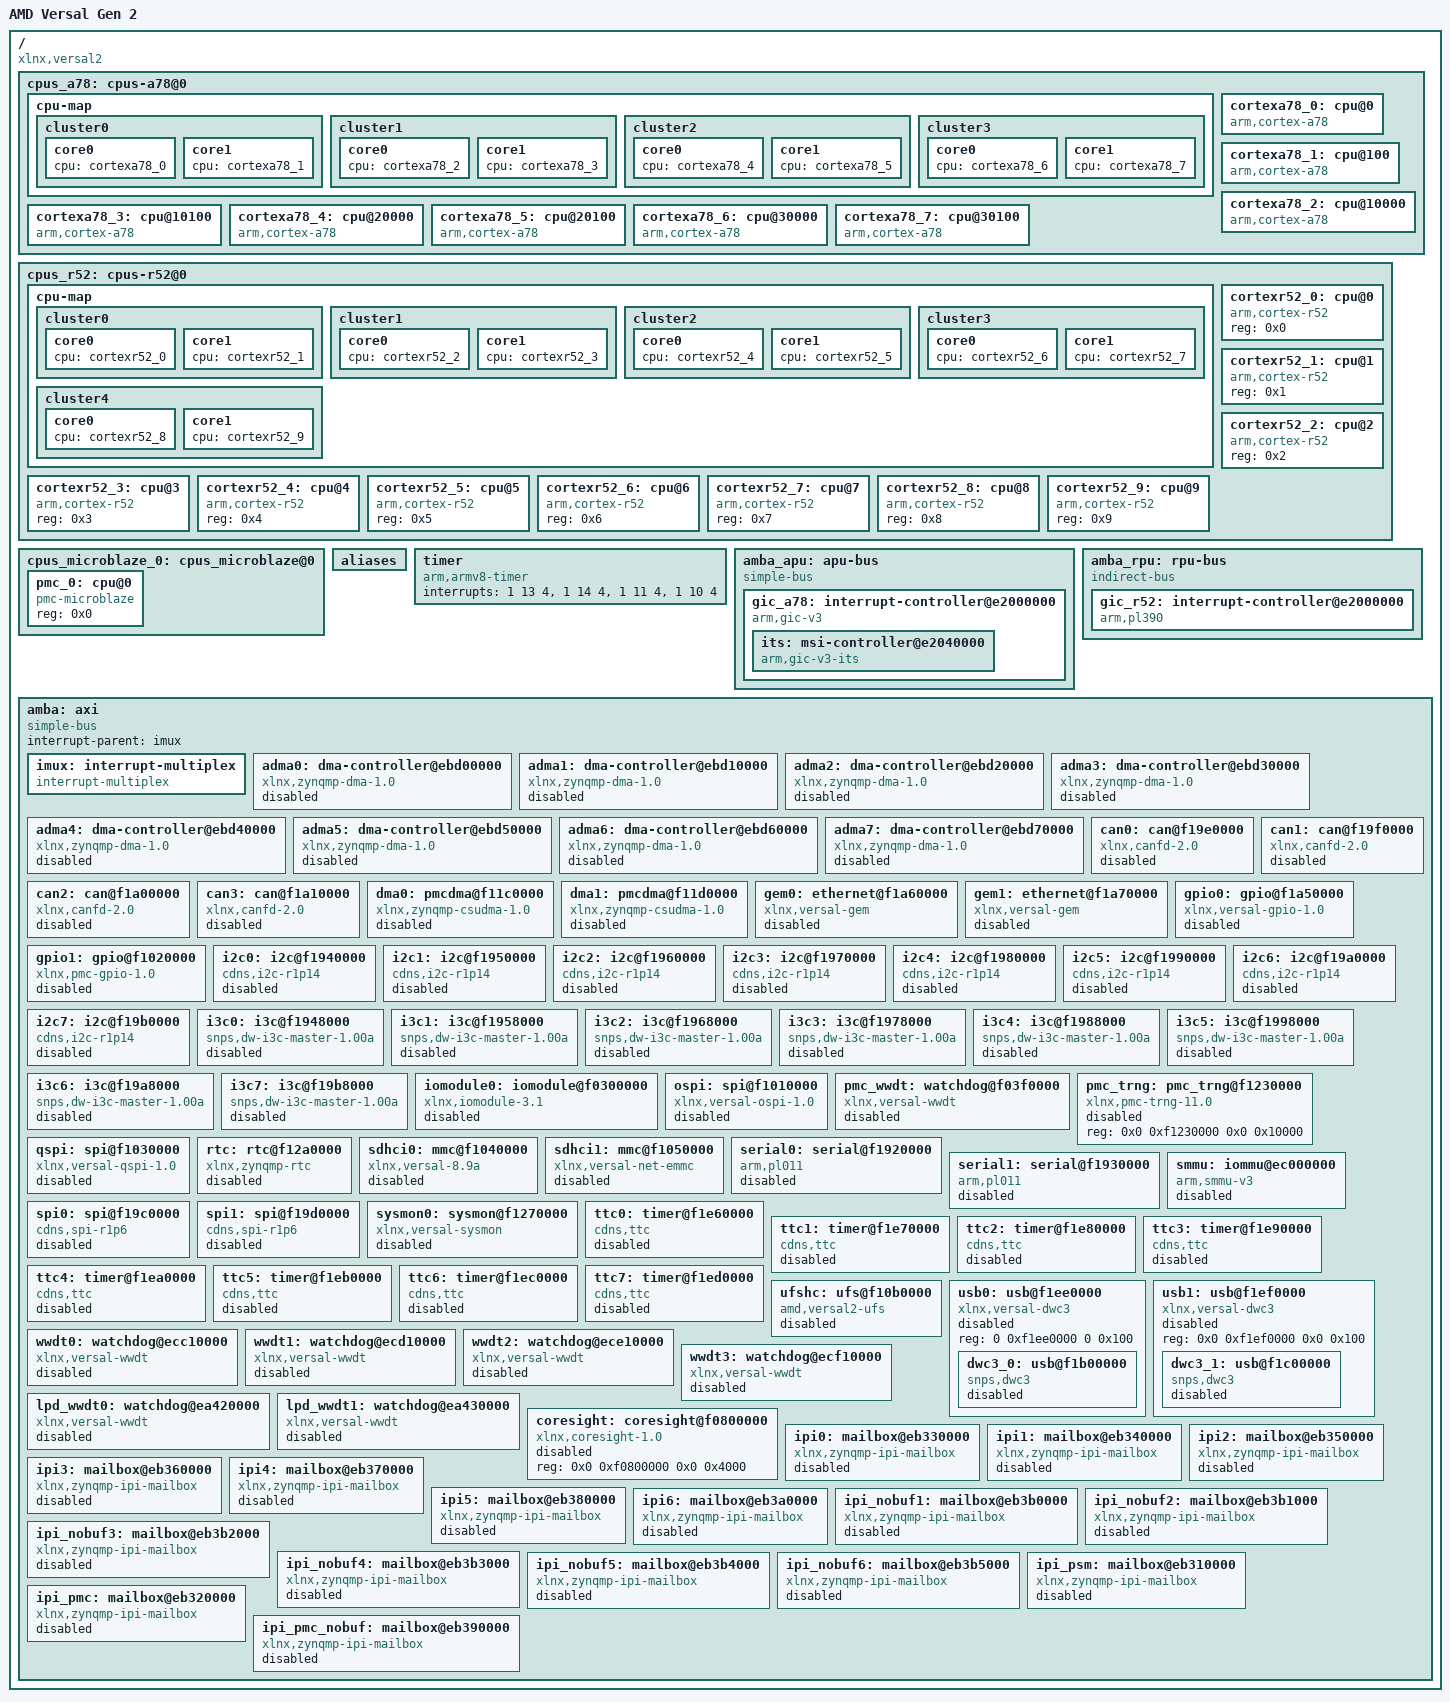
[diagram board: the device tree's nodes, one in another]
// SPDX-License-Identifier: GPL-2.0
/*
 * dts file for AMD Versal Gen 2
 *
 * Copyright (C) 2024, Advanced Micro Devices, Inc.
 *
 * Michal Simek <michal.simek@amd.com>
 */

/dts-v1/;

/ {
	compatible = "xlnx,versal2";
	model = "AMD Versal Gen 2";
	#address-cells = <2>;
	#size-cells = <2>;
	interrupt-parent = <&imux>;

	cpus_a78: cpus-a78@0 {
		#address-cells = <1>;
		#size-cells = <0>;
		cpu-map {
			cluster0 {
				core0 {
					cpu = <&cortexa78_0>;
				};
				core1 {
					cpu = <&cortexa78_1>;
				};
			};
			cluster1 {
				core0 {
					cpu = <&cortexa78_2>;
				};
				core1 {
					cpu = <&cortexa78_3>;
				};
			};
			cluster2 {
				core0 {
					cpu = <&cortexa78_4>;
				};
				core1 {
					cpu = <&cortexa78_5>;
				};
			};
			cluster3 {
				core0 {
					cpu = <&cortexa78_6>;
				};
				core1 {
					cpu = <&cortexa78_7>;
				};
			};
		};

		cortexa78_0: cpu@0 {
			compatible = "arm,cortex-a78";
			device_type = "cpu";
			enable-method = "psci";
			reg = <0>;
		};
		cortexa78_1: cpu@100 {
			compatible = "arm,cortex-a78";
			device_type = "cpu";
			enable-method = "psci";
			reg = <0x100>;
		};
		cortexa78_2: cpu@10000 {
			compatible = "arm,cortex-a78";
			device_type = "cpu";
			enable-method = "psci";
			reg = <0x10000>;
		};
		cortexa78_3: cpu@10100 {
			compatible = "arm,cortex-a78";
			device_type = "cpu";
			enable-method = "psci";
			reg = <0x10100>;
		};
		cortexa78_4: cpu@20000 {
			compatible = "arm,cortex-a78";
			device_type = "cpu";
			enable-method = "psci";
			reg = <0x20000>;
		};
		cortexa78_5: cpu@20100 {
			compatible = "arm,cortex-a78";
			device_type = "cpu";
			enable-method = "psci";
			reg = <0x20100>;
		};
		cortexa78_6: cpu@30000 {
			compatible = "arm,cortex-a78";
			device_type = "cpu";
			enable-method = "psci";
			reg = <0x30000>;
		};
		cortexa78_7: cpu@30100 {
			compatible = "arm,cortex-a78";
			device_type = "cpu";
			enable-method = "psci";
			reg = <0x30100>;
		};
	};

	cpus_r52: cpus-r52@0 {
		#address-cells = <1>;
		#size-cells = <0>;
		cpu-map {
			cluster0 {
				core0 {
					cpu = <&cortexr52_0>;
				};
				core1 {
					cpu = <&cortexr52_1>;
				};
			};

			cluster1 {
				core0 {
					cpu = <&cortexr52_2>;
				};

				core1 {
					cpu = <&cortexr52_3>;
				};
			};

			cluster2 {
				core0 {
					cpu = <&cortexr52_4>;
				};
				core1 {
					cpu = <&cortexr52_5>;
				};
			};

			cluster3 {
				core0 {
					cpu = <&cortexr52_6>;
				};
				core1 {
					cpu = <&cortexr52_7>;
				};
			};

			cluster4 {
				core0 {
					cpu = <&cortexr52_8>;
				};
				core1 {
					cpu = <&cortexr52_9>;
				};
			};
		};

		cortexr52_0: cpu@0 {
			compatible = "arm,cortex-r52";
			device_type = "cpu";
			reg = <0x0>;
		};

		cortexr52_1: cpu@1 {
			compatible = "arm,cortex-r52";
			device_type = "cpu";
			reg = <0x1>;
		};

		cortexr52_2: cpu@2 {
			compatible = "arm,cortex-r52";
			device_type = "cpu";
			reg = <0x2>;
		};

		cortexr52_3: cpu@3 {
			compatible = "arm,cortex-r52";
			device_type = "cpu";
			reg = <0x3>;
		};

		cortexr52_4: cpu@4 {
			compatible = "arm,cortex-r52";
			device_type = "cpu";
			reg = <0x4>;
		};

		cortexr52_5: cpu@5 {
			compatible = "arm,cortex-r52";
			device_type = "cpu";
			reg = <0x5>;
		};

		cortexr52_6: cpu@6 {
			compatible = "arm,cortex-r52";
			device_type = "cpu";
			reg = <0x6>;
		};

		cortexr52_7: cpu@7 {
			compatible = "arm,cortex-r52";
			device_type = "cpu";
			reg = <0x7>;
		};

		cortexr52_8: cpu@8 {
			compatible = "arm,cortex-r52";
			device_type = "cpu";
			reg = <0x8>;
		};

		cortexr52_9: cpu@9 {
			compatible = "arm,cortex-r52";
			device_type = "cpu";
			reg = <0x9>;
		};
	};

	cpus_microblaze_0: cpus_microblaze@0 {
		#address-cells = <1>;
		#size-cells = <0>;
		pmc_0: cpu@0 {
			compatible = "pmc-microblaze";
			device_type = "cpu";
			reg = <0x0>;
		};
	};

	aliases {
		serial0 = &serial0;
		serial1 = &serial1;
		mmc0 = &sdhci0;
		mmc1 = &sdhci1;
		i2c0 = &i2c0;
		i2c1 = &i2c1;
		i2c2 = &i2c2;
		i2c3 = &i2c3;
		i2c4 = &i2c4;
		i2c5 = &i2c5;
		i2c6 = &i2c6;
		i2c7 = &i2c7;
		spi0 = &ospi;
		spi1 = &qspi;
		spi2 = &spi0;
		spi3 = &spi1;
	};

	timer: timer {
		compatible = "arm,armv8-timer";
		interrupts = <1 13 4>, <1 14 4>, <1 11 4>, <1 10 4>;
	};

	amba_apu: apu-bus {
		compatible = "simple-bus";
		#address-cells = <2>;
		#size-cells = <2>;
		ranges;
		interrupt-parent = <&gic_a78>;
		u-boot,dm-pre-reloc;

		gic_a78: interrupt-controller@e2000000 {
			compatible = "arm,gic-v3";
			#interrupt-cells = <3>;
			reg = <0 0xe2000000 0 0x10000>,
			      <0 0xe2060000 0 0x200000>;
			interrupt-controller;
			interrupt-parent = <&gic_a78>;
			interrupts = <1 9 4>;
			#address-cells = <2>;
			#size-cells = <2>;
			ranges;
			its: msi-controller@e2040000 {
				compatible = "arm,gic-v3-its";
				msi-controller;
				#msi-cells = <1>;
				reg = <0 0xe2040000 0 0x20000>;
			};
		};
	};

	// Check the RPU GIC address
	amba_rpu: rpu-bus {
		compatible = "indirect-bus";
		#address-cells = <0x2>;
		#size-cells = <0x2>;
		ranges;
		interrupt-parent = <&gic_r52>;
		u-boot,dm-pre-reloc;

		gic_r52: interrupt-controller@e2000000 {
			compatible = "arm,pl390";
			#interrupt-cells = <3>;
			interrupt-controller;
			interrupt-parent = <&gic_r52>;
			interrupts = <1 9 4>;
			#address-cells = <2>;
			#size-cells = <2>;
			reg = <0x0 0xe2000000 0x0 0x1000>;
		};
	};

	amba: axi {
		compatible = "simple-bus";
		bootph-all;
		#address-cells = <2>;
		#size-cells = <2>;
		ranges;
		interrupt-parent = <&imux>;

		// check imux entries
		/* Proxy Interrupt Controller */
		imux: interrupt-multiplex {
			compatible = "interrupt-multiplex";
			#address-cells = <0x0>;
			#interrupt-cells = <3>;
			interrupt-controller;
			interrupt-parent = <&gic_a78>, <&gic_r52>;
			/* mask for address cells, mask for interrupt cells of the children */
			interrupt-map-mask = <0x0 0xffff 0x0>;
			/* 1:1 mapping of all interrupts to gic_a78 and gic_r52 */
			/* child address cells, child interrupt cells, parent, parent interrupt cells */
			interrupt-map = <0x0 0x14 0x0 &gic_a78 0x0 0x14 0x4>,
					<0x0 0x15 0x0 &gic_a78 0x0 0x15 0x4>,
					<0x0 0x16 0x0 &gic_a78 0x0 0x16 0x4>,
					<0x0 0x17 0x0 &gic_a78 0x0 0x17 0x4>,
					<0x0 0x18 0x0 &gic_a78 0x0 0x18 0x4>,
					<0x0 0x19 0x0 &gic_a78 0x0 0x19 0x4>,
					<0x0 0x1a 0x0 &gic_a78 0x0 0x1a 0x4>,
					<0x0 0x1b 0x0 &gic_a78 0x0 0x1b 0x4>,
					<0x0 0x1c 0x0 &gic_a78 0x0 0x1c 0x4>,
					<0x0 0x1d 0x0 &gic_a78 0x0 0x1d 0x4>,
					<0x0 0x21 0x0 &gic_a78 0x0 0x21 0x4>,
					<0x0 0x22 0x0 &gic_a78 0x0 0x22 0x4>,
					<0x0 0x26 0x0 &gic_a78 0x0 0x26 0x4>,
					<0x0 0x27 0x0 &gic_a78 0x0 0x27 0x4>,
					<0x0 0x29 0x0 &gic_a78 0x0 0x29 0x4>,
					<0x0 0x2b 0x0 &gic_a78 0x0 0x2b 0x4>,
					<0x0 0x2c 0x0 &gic_a78 0x0 0x2c 0x4>,
					<0x0 0x2d 0x0 &gic_a78 0x0 0x2d 0x4>,
					<0x0 0x2e 0x0 &gic_a78 0x0 0x2e 0x4>,
					<0x0 0x2f 0x0 &gic_a78 0x0 0x2f 0x4>,
					<0x0 0x30 0x0 &gic_a78 0x0 0x30 0x4>,
					<0x0 0x31 0x0 &gic_a78 0x0 0x31 0x4>,
					<0x0 0x32 0x0 &gic_a78 0x0 0x32 0x4>,
					<0x0 0x33 0x0 &gic_a78 0x0 0x33 0x4>,
					<0x0 0x34 0x0 &gic_a78 0x0 0x34 0x4>,
					<0x0 0x35 0x0 &gic_a78 0x0 0x35 0x4>,
					<0x0 0x36 0x0 &gic_a78 0x0 0x36 0x4>,
					<0x0 0x48 0x0 &gic_a78 0x0 0x48 0x4>,
					<0x0 0x49 0x0 &gic_a78 0x0 0x49 0x4>,
					<0x0 0x4a 0x0 &gic_a78 0x0 0x4a 0x4>,
					<0x0 0x4b 0x0 &gic_a78 0x0 0x4b 0x4>,
					<0x0 0x4c 0x0 &gic_a78 0x0 0x4c 0x4>,
					<0x0 0x4d 0x0 &gic_a78 0x0 0x4d 0x4>,
					<0x0 0x4e 0x0 &gic_a78 0x0 0x4e 0x4>,
					<0x0 0x4f 0x0 &gic_a78 0x0 0x4f 0x4>,
					<0x0 0x62 0x0 &gic_a78 0x0 0x62 0x4>,
					<0x0 0x63 0x0 &gic_a78 0x0 0x63 0x4>,
					<0x0 0xa9 0x0 &gic_a78 0x0 0xa9 0x4>,
					<0x0 0xb4 0x0 &gic_a78 0x0 0xb4 0x4>,
					<0x0 0xb5 0x0 &gic_a78 0x0 0xb5 0x4>,
					<0x0 0xb6 0x0 &gic_a78 0x0 0xb6 0x4>,
					<0x0 0xb7 0x0 &gic_a78 0x0 0xb7 0x4>,
					<0x0 0xb9 0x0 &gic_a78 0x0 0xb9 0x4>,
					<0x0 0xbe 0x0 &gic_a78 0x0 0xbe 0x4>,
					<0x0 0xbf 0x0 &gic_a78 0x0 0xbf 0x4>,
					<0x0 0xc8 0x0 &gic_a78 0x0 0xc8 0x4>,
					<0x0 0xc9 0x0 &gic_a78 0x0 0xc9 0x4>,
					<0x0 0x8b 0x0 &gic_a78 0x0 0x8b 0x1>,
					<0x0 0x8c 0x0 &gic_a78 0x0 0x8c 0x1>,
					<0x0 0x8f 0x0 &gic_a78 0x0 0x8f 0x1>,
					<0x0 0x90 0x0 &gic_a78 0x0 0x90 0x1>,
					<0x0 0x93 0x0 &gic_a78 0x0 0x93 0x1>,
					<0x0 0x94 0x0 &gic_a78 0x0 0x94 0x1>,
					<0x0 0xa4 0x0 &gic_a78 0x0 0xa4 0x1>,
					<0x0 0xa5 0x0 &gic_a78 0x0 0xa5 0x1>,
					<0x0 0x14 0x0 &gic_r52 0x0 0x14 0x4>,
					<0x0 0x15 0x0 &gic_r52 0x0 0x15 0x4>,
					<0x0 0x16 0x0 &gic_r52 0x0 0x16 0x4>,
					<0x0 0x17 0x0 &gic_r52 0x0 0x17 0x4>,
					<0x0 0x18 0x0 &gic_r52 0x0 0x18 0x4>,
					<0x0 0x19 0x0 &gic_r52 0x0 0x19 0x4>,
					<0x0 0x1a 0x0 &gic_r52 0x0 0x1a 0x4>,
					<0x0 0x1b 0x0 &gic_r52 0x0 0x1b 0x4>,
					<0x0 0x1c 0x0 &gic_r52 0x0 0x1c 0x4>,
					<0x0 0x1d 0x0 &gic_r52 0x0 0x1d 0x4>,
					<0x0 0x21 0x0 &gic_r52 0x0 0x21 0x4>,
					<0x0 0x22 0x0 &gic_r52 0x0 0x22 0x4>,
					<0x0 0x26 0x0 &gic_r52 0x0 0x26 0x4>,
					<0x0 0x27 0x0 &gic_r52 0x0 0x27 0x4>,
					<0x0 0x29 0x0 &gic_r52 0x0 0x29 0x4>,
					<0x0 0x2b 0x0 &gic_r52 0x0 0x2b 0x4>,
					<0x0 0x2c 0x0 &gic_r52 0x0 0x2c 0x4>,
					<0x0 0x2d 0x0 &gic_r52 0x0 0x2d 0x4>,
					<0x0 0x2e 0x0 &gic_r52 0x0 0x2e 0x4>,
					<0x0 0x2f 0x0 &gic_r52 0x0 0x2f 0x4>,
					<0x0 0x30 0x0 &gic_r52 0x0 0x30 0x4>,
					<0x0 0x31 0x0 &gic_r52 0x0 0x31 0x4>,
					<0x0 0x32 0x0 &gic_r52 0x0 0x32 0x4>,
					<0x0 0x33 0x0 &gic_r52 0x0 0x33 0x4>,
					<0x0 0x34 0x0 &gic_r52 0x0 0x34 0x4>,
					<0x0 0x35 0x0 &gic_r52 0x0 0x35 0x4>,
					<0x0 0x36 0x0 &gic_r52 0x0 0x36 0x4>,
					<0x0 0x48 0x0 &gic_r52 0x0 0x48 0x4>,
					<0x0 0x49 0x0 &gic_r52 0x0 0x49 0x4>,
					<0x0 0x4a 0x0 &gic_r52 0x0 0x4a 0x4>,
					<0x0 0x4b 0x0 &gic_r52 0x0 0x4b 0x4>,
					<0x0 0x4c 0x0 &gic_r52 0x0 0x4c 0x4>,
					<0x0 0x4d 0x0 &gic_r52 0x0 0x4d 0x4>,
					<0x0 0x4e 0x0 &gic_r52 0x0 0x4e 0x4>,
					<0x0 0x4f 0x0 &gic_r52 0x0 0x4f 0x4>,
					<0x0 0x62 0x0 &gic_r52 0x0 0x62 0x4>,
					<0x0 0x63 0x0 &gic_r52 0x0 0x63 0x4>,
					<0x0 0xa9 0x0 &gic_r52 0x0 0xa9 0x4>,
					<0x0 0xb4 0x0 &gic_r52 0x0 0xb4 0x4>,
					<0x0 0xb5 0x0 &gic_r52 0x0 0xb5 0x4>,
					<0x0 0xb6 0x0 &gic_r52 0x0 0xb6 0x4>,
					<0x0 0xb7 0x0 &gic_r52 0x0 0xb7 0x4>,
					<0x0 0xb9 0x0 &gic_r52 0x0 0xb9 0x4>,
					<0x0 0xbe 0x0 &gic_r52 0x0 0xbe 0x4>,
					<0x0 0xbf 0x0 &gic_r52 0x0 0xbf 0x4>,
					<0x0 0xc8 0x0 &gic_r52 0x0 0xc8 0x4>,
					<0x0 0xc9 0x0 &gic_r52 0x0 0xc9 0x4>,
					<0x0 0x8b 0x0 &gic_r52 0x0 0x8b 0x1>,
					<0x0 0x8c 0x0 &gic_r52 0x0 0x8c 0x1>,
					<0x0 0x8f 0x0 &gic_r52 0x0 0x8f 0x1>,
					<0x0 0x90 0x0 &gic_r52 0x0 0x90 0x1>,
					<0x0 0x93 0x0 &gic_r52 0x0 0x93 0x1>,
					<0x0 0x94 0x0 &gic_r52 0x0 0x94 0x1>,
					<0x0 0xa4 0x0 &gic_r52 0x0 0xa4 0x1>,
					<0x0 0xa5 0x0 &gic_r52 0x0 0xa5 0x1>;
		};

		adma0: dma-controller@ebd00000 {
			compatible = "xlnx,zynqmp-dma-1.0";
			status = "disabled";
			reg = <0 0xebd00000 0 0x1000>;
			interrupt-parent = <&imux>;
			interrupts = <0 72 4>;
			clock-names = "clk_main", "clk_apb";
			#dma-cells = <1>;
			xlnx,bus-width = <64>;
		};

		adma1: dma-controller@ebd10000 {
			compatible = "xlnx,zynqmp-dma-1.0";
			status = "disabled";
			reg = <0 0xebd10000 0 0x1000>;
			interrupt-parent = <&imux>;
			interrupts = <0 73 4>;
			clock-names = "clk_main", "clk_apb";
			#dma-cells = <1>;
			xlnx,bus-width = <64>;
		};

		adma2: dma-controller@ebd20000 {
			compatible = "xlnx,zynqmp-dma-1.0";
			status = "disabled";
			reg = <0 0xebd20000 0 0x1000>;
			interrupt-parent = <&imux>;
			interrupts = <0 74 4>;
			clock-names = "clk_main", "clk_apb";
			#dma-cells = <1>;
			xlnx,bus-width = <64>;
		};

		adma3: dma-controller@ebd30000 {
			compatible = "xlnx,zynqmp-dma-1.0";
			status = "disabled";
			reg = <0 0xebd30000 0 0x1000>;
			interrupt-parent = <&imux>;
			interrupts = <0 75 4>;
			clock-names = "clk_main", "clk_apb";
			#dma-cells = <1>;
			xlnx,bus-width = <64>;
		};

		adma4: dma-controller@ebd40000 {
			compatible = "xlnx,zynqmp-dma-1.0";
			status = "disabled";
			reg = <0 0xebd40000 0 0x1000>;
			interrupt-parent = <&imux>;
			interrupts = <0 76 4>;
			clock-names = "clk_main", "clk_apb";
			#dma-cells = <1>;
			xlnx,bus-width = <64>;
		};

		adma5: dma-controller@ebd50000 {
			compatible = "xlnx,zynqmp-dma-1.0";
			status = "disabled";
			reg = <0 0xebd50000 0 0x1000>;
			interrupt-parent = <&imux>;
			interrupts = <0 77 4>;
			clock-names = "clk_main", "clk_apb";
			#dma-cells = <1>;
			xlnx,bus-width = <64>;
		};

		adma6: dma-controller@ebd60000 {
			compatible = "xlnx,zynqmp-dma-1.0";
			status = "disabled";
			reg = <0 0xebd60000 0 0x1000>;
			interrupt-parent = <&imux>;
			interrupts = <0 78 4>;
			clock-names = "clk_main", "clk_apb";
			#dma-cells = <1>;
			xlnx,bus-width = <64>;
		};

		adma7: dma-controller@ebd70000 {
			compatible = "xlnx,zynqmp-dma-1.0";
			status = "disabled";
			reg = <0 0xebd70000 0 0x1000>;
			interrupt-parent = <&imux>;
			interrupts = <0 79 4>;
			clock-names = "clk_main", "clk_apb";
			#dma-cells = <1>;
			xlnx,bus-width = <64>;
		};

		can0: can@f19e0000 {
			compatible = "xlnx,canfd-2.0";
			status = "disabled";
			reg = <0 0xf19e0000 0 0x6000>;
			interrupt-parent = <&imux>;
			interrupts = <0 27 4>;
			clock-names = "can_clk", "s_axi_aclk";
			rx-fifo-depth = <64>;
			tx-mailbox-count = <32>;
		};

		can1: can@f19f0000 {
			compatible = "xlnx,canfd-2.0";
			status = "disabled";
			reg = <0 0xf19f0000 0 0x6000>;
			interrupt-parent = <&imux>;
			interrupts = <0 28 4>;
			clock-names = "can_clk", "s_axi_aclk";
			rx-fifo-depth = <64>;
			tx-mailbox-count = <32>;
		};

		can2: can@f1a00000 {
			compatible = "xlnx,canfd-2.0";
			status = "disabled";
			reg = <0 0xf1a00000 0 0x6000>;
			interrupt-parent = <&imux>;
			interrupts = <0 95 4>;
			clock-names = "can_clk", "s_axi_aclk";
			rx-fifo-depth = <64>;
			tx-mailbox-count = <32>;
		};

		can3: can@f1a10000 {
			compatible = "xlnx,canfd-2.0";
			status = "disabled";
			reg = <0 0xf1a10000 0 0x6000>;
			interrupt-parent = <&imux>;
			interrupts = <0 96 4>;
			clock-names = "can_clk", "s_axi_aclk";
			rx-fifo-depth = <64>;
			tx-mailbox-count = <32>;
		};

		dma0: pmcdma@f11c0000 {
			status = "disabled";
			compatible = "xlnx,zynqmp-csudma-1.0";
			interrupt-parent = <&imux>;
			interrupts = <0 190 4>;
			reg = <0x0 0xf11c0000 0x0 0x10000>;
			xlnx,dma-type = <1>;
		};

		dma1: pmcdma@f11d0000 {
			status = "disabled";
			compatible = "xlnx,zynqmp-csudma-1.0";
			interrupt-parent = <&imux>;
			interrupts = <0 191 4>;
			reg = <0x0 0xf11d0000 0x0 0x10000>;
			xlnx,dma-type = <2>;
		};

		gem0: ethernet@f1a60000 {
			compatible = "xlnx,versal-gem", "cdns,gem";
			status = "disabled";
			reg = <0 0xf1a60000 0 0x1000>;
			interrupt-parent = <&imux>;
			interrupts = <0 39 4>, <0 39 4>;
			clock-names = "pclk", "hclk", "tx_clk", "rx_clk",
				      "tsu_clk";
		};

		gem1: ethernet@f1a70000 {
			compatible = "xlnx,versal-gem", "cdns,gem";
			status = "disabled";
			reg = <0 0xf1a70000 0 0x1000>;
			interrupt-parent = <&imux>;
			interrupts = <0 41 4>, <0 41 4>;
			clock-names = "pclk", "hclk", "tx_clk", "rx_clk",
				      "tsu_clk";
		};

		gpio0: gpio@f1a50000 {
			compatible = "xlnx,versal-gpio-1.0";
			status = "disabled";
			reg = <0 0xf1a50000 0 0x1000>;
			interrupt-parent = <&imux>;
			interrupts = <0 20 4>;
			#gpio-cells = <2>;
			gpio-controller;
			#interrupt-cells = <2>;
			interrupt-controller;
		};

		gpio1: gpio@f1020000 {
			compatible = "xlnx,pmc-gpio-1.0";
			status = "disabled";
			reg = <0 0xf1020000 0 0x1000>;
			interrupt-parent = <&imux>;
			interrupts = <0 202 4>; /* FIXME */
			#gpio-cells = <2>;
			gpio-controller;
			#interrupt-cells = <2>;
			interrupt-controller;
		};

		i2c0: i2c@f1940000 {
			compatible = "cdns,i2c-r1p14";
			status = "disabled";
			reg = <0 0xf1940000 0 0x1000>;
			interrupt-parent = <&imux>;
			interrupts = <0 21 4>;
		};

		i2c1: i2c@f1950000 {
			compatible = "cdns,i2c-r1p14";
			status = "disabled";
			reg = <0 0xf1950000 0 0x1000>;
			interrupt-parent = <&imux>;
			interrupts = <0 22 4>;
		};

		i2c2: i2c@f1960000 {
			compatible = "cdns,i2c-r1p14";
			status = "disabled";
			reg = <0 0xf1960000 0 0x1000>;
			interrupt-parent = <&imux>;
			interrupts = <0 11 4>;
		};

		i2c3: i2c@f1970000 {
			compatible = "cdns,i2c-r1p14";
			status = "disabled";
			reg = <0 0xf1970000 0 0x1000>;
			interrupt-parent = <&imux>;
			interrupts = <0 12 4>;
		};

		i2c4: i2c@f1980000 {
			compatible = "cdns,i2c-r1p14";
			status = "disabled";
			reg = <0 0xf1980000 0 0x1000>;
			interrupt-parent = <&imux>;
			interrupts = <0 13 4>;
		};

		i2c5: i2c@f1990000 {
			compatible = "cdns,i2c-r1p14";
			status = "disabled";
			reg = <0 0xf1990000 0 0x1000>;
			interrupt-parent = <&imux>;
			interrupts = <0 100 4>;
		};

		i2c6: i2c@f19a0000 {
			compatible = "cdns,i2c-r1p14";
			status = "disabled";
			reg = <0 0xf19a0000 0 0x1000>;
			interrupt-parent = <&imux>;
			interrupts = <0 101 4>;
		};

		i2c7: i2c@f19b0000 {
			compatible = "cdns,i2c-r1p14";
			status = "disabled";
			reg = <0 0xf19b0000 0 0x1000>;
			interrupt-parent = <&imux>;
			interrupts = <0 102 0x04>;
		};

		i3c0: i3c@f1948000 {
			compatible = "snps,dw-i3c-master-1.00a";
			status = "disabled";
			#address-cells = <3>;
			#size-cells = <0>;
			reg = <0 0xf1948000 0 0x1000>;
			interrupts = <0 21 4>;
		};

		i3c1: i3c@f1958000 {
			compatible = "snps,dw-i3c-master-1.00a";
			status = "disabled";
			#address-cells = <3>;
			#size-cells = <0>;
			reg = <0 0xf1958000 0 0x1000>;
			interrupts = <0 22 4>;
		};

		i3c2: i3c@f1968000 {
			compatible = "snps,dw-i3c-master-1.00a";
			status = "disabled";
			#address-cells = <3>;
			#size-cells = <0>;
			reg = <0 0xf1960000 0 0x1000>;
			interrupts = <0 11 4>;
		};

		i3c3: i3c@f1978000 {
			compatible = "snps,dw-i3c-master-1.00a";
			status = "disabled";
			#address-cells = <3>;
			#size-cells = <0>;
			reg = <0 0xf1970000 0 0x1000>;
			interrupts = <0 12 4>;
		};

		i3c4: i3c@f1988000 {
			compatible = "snps,dw-i3c-master-1.00a";
			status = "disabled";
			#address-cells = <3>;
			#size-cells = <0>;
			reg = <0 0xf1980000 0 0x1000>;
			interrupts = <0 13 4>;
		};

		i3c5: i3c@f1998000 {
			compatible = "snps,dw-i3c-master-1.00a";
			status = "disabled";
			#address-cells = <3>;
			#size-cells = <0>;
			reg = <0 0xf1990000 0 0x1000>;
			interrupts = <0 100 4>;
		};

		i3c6: i3c@f19a8000 {
			compatible = "snps,dw-i3c-master-1.00a";
			status = "disabled";
			#address-cells = <3>;
			#size-cells = <0>;
			reg = <0 0xf19a0000 0 0x1000>;
			interrupts = <0 101 4>;
		};

		i3c7: i3c@f19b8000 {
			compatible = "snps,dw-i3c-master-1.00a";
			status = "disabled";
			#address-cells = <3>;
			#size-cells = <0>;
			reg = <0 0xf19b0000 0 0x1000>;
			interrupts = <0 102 4>;
		};

		iomodule0: iomodule@f0300000 {
			status = "disabled";
			compatible = "xlnx,iomodule-3.1";
			reg = <0x0 0xf0300000 0x0 0x1000>, <0xFFFFFFFF 0xFFFFFFFF 0x0 0xE0000>;
		};

		ospi: spi@f1010000 {
			compatible = "xlnx,versal-ospi-1.0", "cdns,qspi-nor";
			status = "disabled";
			reg = <0 0xf1010000 0 0x10000>,
			      <0 0xc0000000 0 0x20000000>;
			interrupt-parent = <&imux>;
			interrupts = <0 216 4>;
			cdns,fifo-depth = <256>;
			cdns,fifo-width = <4>;
			cdns,is-dma = <1>; /* u-boot specific */
			cdns,trigger-address = <0xc0000000>;
		};

		pmc_wwdt: watchdog@f03f0000 {
			compatible = "xlnx,versal-wwdt";
			status = "disabled";
			reg = <0 0xf03f0000 0 0x10000>;
			interrupt-names = "wdt", "wwdt_reset_pending", "gwdt", "gwdt_reset_pending";
			interrupts = <0 217 1>, <0 218 1>, <0 219 1>, <0 220 1>;
			interrupt-parent = <&imux>;
			timeout-sec = <30>;
		};

		pmc_trng: pmc_trng@f1230000 {
			compatible = "xlnx,pmc-trng-11.0";
			status = "disabled";
			reg = <0x0 0xf1230000 0x0 0x10000>;
		};

		qspi: spi@f1030000 {
			compatible = "xlnx,versal-qspi-1.0";
			status = "disabled";
			reg = <0 0xf1030000 0 0x1000>; /* missing one more reg range - checking with Sai */
			interrupt-parent = <&imux>;
			interrupts = <0 217 4>;
			clock-names = "ref_clk", "pclk";
		};

		rtc: rtc@f12a0000 {
			compatible = "xlnx,zynqmp-rtc";
			status = "disabled";
			reg = <0 0xf12a0000 0 0x100>;
			interrupt-parent = <&imux>;
			interrupts = <0 200 4>, <0 201 4>;
			interrupt-names = "alarm", "sec";
			calibration = <0x8000>;
		};

		sdhci0: mmc@f1040000 {
			compatible = "xlnx,versal-8.9a", "arasan,sdhci-8.9a";
			status = "disabled";
			reg = <0 0xf1040000 0 0x10000>;
			interrupt-parent = <&imux>;
			interrupts = <0 218 4>;
			clock-names = "clk_xin", "clk_ahb", "gate";
			#clock-cells = <1>;
			clock-output-names = "clk_out_sd0", "clk_in_sd0";
		};

		sdhci1: mmc@f1050000 {
			compatible = "xlnx,versal-net-emmc";
			status = "disabled";
			reg = <0 0xf1050000 0 0x10000>;
			interrupt-parent = <&imux>;
			interrupts = <0 220 4>;
			clock-names = "clk_xin", "clk_ahb", "gate";
			#clock-cells = <1>;
			clock-output-names = "clk_out_sd1", "clk_in_sd1";
		};

		serial0: serial@f1920000 {
			bootph-all;
			compatible = "arm,pl011", "arm,primecell";
			status = "disabled";
			reg = <0 0xf1920000 0 0x1000>;
			interrupt-parent = <&imux>;
			interrupts = <0 25 4>;
			reg-io-width = <4>;
			clock-names = "uartclk", "apb_pclk";
		};

		serial1: serial@f1930000 {
			bootph-all;
			compatible = "arm,pl011", "arm,primecell";
			status = "disabled";
			reg = <0 0xf1930000 0 0x1000>;
			interrupt-parent = <&imux>;
			interrupts = <0 26 4>;
			reg-io-width = <4>;
			clock-names = "uartclk", "apb_pclk";
		};

		smmu: iommu@ec000000 {
			compatible = "arm,smmu-v3";
			status = "disabled";
			reg = <0 0xec000000 0 0x40000>;
			#iommu-cells = <1>;
			interrupt-names = "combined";
			interrupt-parent = <&imux>;
			interrupts = <0 169 4>;
			dma-coherent;
		};

		spi0: spi@f19c0000 {
			compatible = "cdns,spi-r1p6";
			status = "disabled";
			interrupts = <0 23 4>;
			reg = <0 0xf19c0000 0 0x1000>;
			clock-names = "ref_clk", "pclk";
		};

		spi1: spi@f19d0000 {
			compatible = "cdns,spi-r1p6";
			status = "disabled";
			interrupts = <0 24 4>;
			reg = <0 0xf19d0000 0 0x1000>;
			clock-names = "ref_clk", "pclk";
		};

		sysmon0: sysmon@f1270000 {
			compatible = "xlnx,versal-sysmon";
			status = "disabled";
			reg = <0x0 0xf1270000 0x0 0x4000>;
			interrupts = <0 202 4>;
			xlnx,numchannels = /bits/8 <0>;
		};

		ttc0: timer@f1e60000 {
			compatible = "cdns,ttc";
			status = "disabled";
			interrupt-parent = <&imux>;
			interrupts = <0 43 4>, <0 43 4>, <0 43 4>;
			timer-width = <32>;
			reg = <0 0xf1e60000 0x0 0x1000>;
		};

		ttc1: timer@f1e70000 {
			compatible = "cdns,ttc";
			status = "disabled";
			interrupt-parent = <&imux>;
			interrupts = <0 44 4>, <0 44 4>, <0 44 4>;
			timer-width = <32>;
			reg = <0 0xf1e70000 0 0x1000>;
		};

		ttc2: timer@f1e80000 {
			compatible = "cdns,ttc";
			status = "disabled";
			interrupt-parent = <&imux>;
			interrupts = <0 45 4>, <0 45 4>, <0 45 4>;
			timer-width = <32>;
			reg = <0 0xf1e80000 0 0x1000>;
		};

		ttc3: timer@f1e90000 {
			compatible = "cdns,ttc";
			status = "disabled";
			interrupt-parent = <&imux>;
			interrupts = <0 46 4>, <0 46 4>, <0 46 4>;
			timer-width = <32>;
			reg = <0 0xf1e90000 0 0x1000>;
		};

		ttc4: timer@f1ea0000 {
			compatible = "cdns,ttc";
			status = "disabled";
			interrupt-parent = <&imux>;
			interrupts = <0 47 4>, <0 47 4>, <0 47 4>;
			timer-width = <32>;
			reg = <0 0xf1ea0000 0 0x1000>;
		};

		ttc5: timer@f1eb0000 {
			compatible = "cdns,ttc";
			status = "disabled";
			interrupt-parent = <&imux>;
			interrupts = <0 48 4>, <0 48 4>, <0 48 4>;
			timer-width = <32>;
			reg = <0 0xf1eb0000 0 0x1000>;
		};

		ttc6: timer@f1ec0000 {
			compatible = "cdns,ttc";
			status = "disabled";
			interrupt-parent = <&imux>;
			interrupts = <0 49 4>, <0 49 4>, <0 49 4>;
			timer-width = <32>;
			reg = <0 0xf1ec0000 0 0x1000>;
		};

		ttc7: timer@f1ed0000 {
			compatible = "cdns,ttc";
			status = "disabled";
			interrupt-parent = <&imux>;
			interrupts = <0 50 4>, <0 50 4>, <0 50 4>;
			timer-width = <32>;
			reg = <0 0xf1ed0000 0 0x1000>;
		};

		ufshc: ufs@f10b0000 {
			compatible = "amd,versal2-ufs", "cdns,ufshc-m31-16nm", "jedec,ufs-2.0";
			status = "disabled";
			reg = <0 0xf10b0000 0 0x100>;
			freq-table-hz = <250000000 250000000>, <19200000 19200000>, <19200000 19200000>;
			clock-names = "core_clk", "phy_clk", "ref_clk";
			dma-coherent;
		};

		usb0: usb@f1ee0000 {
			compatible = "xlnx,versal-dwc3";
			status = "disabled";
			reg = <0 0xf1ee0000 0 0x100>;
			clock-names = "bus_clk", "ref_clk";
			ranges;
			#address-cells = <2>;
			#size-cells = <2>;

			dwc3_0: usb@f1b00000  {
				compatible = "snps,dwc3";
				status = "disabled";
				reg = <0 0xf1b00000 0 0x10000>;
				interrupt-names = "host", "peripheral", "otg", "wakeup";
				interrupts = <0 29 4>, <0 29 4>, <0 33 4>, <0 98 4>;
				interrupt-parent = <&imux>;
				snps,dis_u2_susphy_quirk;
				snps,dis_u3_susphy_quirk;
				snps,quirk-frame-length-adjustment = <0x20>;
				snps,usb3_lpm_capable;
				clock-names = "ref";
			};
		};

		usb1: usb@f1ef0000 {
			compatible = "xlnx,versal-dwc3";
			status = "disabled";
			reg = <0x0 0xf1ef0000 0x0 0x100>;
			clock-names = "bus_clk", "ref_clk";
			ranges;
			#address-cells = <2>;
			#size-cells = <2>;

			dwc3_1: usb@f1c00000  {
				compatible = "snps,dwc3";
				status = "disabled";
				reg = <0x0 0xf1c00000 0x0 0x10000>;
				interrupt-names = "host", "peripheral", "otg", "wakeup";
				interrupts = <0 34 4>, <0 34 4>, <0 38 4>, <0 99 4>;
				interrupt-parent = <&imux>;
				snps,dis_u2_susphy_quirk;
				snps,dis_u3_susphy_quirk;
				snps,quirk-frame-length-adjustment = <0x20>;
				snps,usb3_lpm_capable;
				clock-names = "ref";
			};
		};

		wwdt0: watchdog@ecc10000 {
			compatible = "xlnx,versal-wwdt";
			status = "disabled";
			reg = <0 0xecc10000 0 0x10000>;
			interrupt-names = "wdt", "wwdt_reset_pending", "gwdt", "gwdt_reset_pending";
			interrupt-parent = <&imux>;
			interrupts = <0 139 1>, <0 140 1>, <0 141 1>, <0 142 1>;
			timeout-sec = <30>;
		};

		wwdt1: watchdog@ecd10000 {
			compatible = "xlnx,versal-wwdt";
			status = "disabled";
			reg = <0 0xecd10000 0 0x10000>;
			interrupt-names = "wdt", "wwdt_reset_pending", "gwdt", "gwdt_reset_pending";
			interrupt-parent = <&imux>;
			interrupts = <0 143 1>, <0 144 1>, <0 145 1>, <0 146 1>;
			timeout-sec = <30>;
		};

		wwdt2: watchdog@ece10000 {
			compatible = "xlnx,versal-wwdt";
			status = "disabled";
			reg = <0 0xece10000 0 0x10000>;
			interrupt-names = "wdt", "wwdt_reset_pending", "gwdt", "gwdt_reset_pending";
			interrupt-parent = <&imux>;
			interrupts = <0 147 1>,  <0 148 1>,  <0 149 1>,  <0 150 1>;
			timeout-sec = <30>;
		};

		wwdt3: watchdog@ecf10000 {
			compatible = "xlnx,versal-wwdt";
			status = "disabled";
			reg = <0 0xecf10000 0 0x10000>;
			interrupt-names = "wdt", "wwdt_reset_pending", "gwdt", "gwdt_reset_pending";
			interrupt-parent = <&imux>;
			interrupts = <0 164 1>, <0 165 1>,  <0 166 1>,  <0 167 1>;
			timeout-sec = <30>;
		};

		lpd_wwdt0: watchdog@ea420000 {
			compatible = "xlnx,versal-wwdt";
			status = "disabled";
			reg = <0 0xea420000 0 0x10000>;
			interrupt-names = "wdt", "wwdt_reset_pending", "gwdt", "gwdt_reset_pending";
			interrupts = <0 82 1>, <0 84 1>, <0 86 1>, <0 87 1>;
			interrupt-parent = <&imux>;
			timeout-sec = <30>;
		};

		lpd_wwdt1: watchdog@ea430000 {
			compatible = "xlnx,versal-wwdt";
			status = "disabled";
			reg = <0 0xea430000 0 0x10000>;
			interrupt-names = "wdt", "wwdt_reset_pending", "gwdt", "gwdt_reset_pending";
			interrupts = <0 83 1>, <0 85 1>, <0 88 1>, <0 89 1>;
			interrupt-parent = <&imux>;
			timeout-sec = <30>;
		};

		coresight: coresight@f0800000 {
		    compatible = "xlnx,coresight-1.0";
		    status = "disabled";
		    reg = <0x0 0xf0800000 0x0 0x4000>;
		};

		ipi0: mailbox@eb330000 {
			status = "disabled";
			compatible = "xlnx,zynqmp-ipi-mailbox";
			interrupt-parent = <&imux>;
			interrupts = <0 57 4>;
			reg = <0x0 0xEB330000U 0x0 0x20>;
			xlnx,ipi-bitmask = <0x4>;
			xlnx,ipi-id = <2>;
			xlnx,ipi-buf-index = <0x2>;
			#address-cells = <2>;
			#size-cells = <2>;
			ranges;
		};

		ipi1: mailbox@eb340000 {
			status = "disabled";
			compatible = "xlnx,zynqmp-ipi-mailbox";
			interrupt-parent = <&imux>;
			interrupts = <0 58 4>;
			reg = <0x0 0xEB340000U 0x0 0x20>;
			xlnx,ipi-bitmask = <0x8>;
			xlnx,ipi-id = <3>;
			xlnx,ipi-buf-index = <0x3>;
			#address-cells = <2>;
			#size-cells = <2>;
			ranges;
		};

		ipi2: mailbox@eb350000 {
			status = "disabled";
			compatible = "xlnx,zynqmp-ipi-mailbox";
			interrupt-parent = <&imux>;
			interrupts = <0 59 4>;
			reg = <0x0 0xEB350000U 0x0 0x20>;
			xlnx,ipi-bitmask = <0x10>;
			xlnx,ipi-id = <4>;
			xlnx,ipi-buf-index = <0x4>;
			#address-cells = <2>;
			#size-cells = <2>;
			ranges;
		};

		ipi3: mailbox@eb360000 {
			status = "disabled";
			compatible = "xlnx,zynqmp-ipi-mailbox";
			interrupt-parent = <&imux>;
			interrupts = <0 60 4>;
			reg = <0x0 0xEB360000U 0x0 0x20>;
			xlnx,ipi-bitmask = <0x20>;
			xlnx,ipi-id = <5>;
			xlnx,ipi-buf-index = <0x5>;
			#address-cells = <2>;
			#size-cells = <2>;
			ranges;
		};


		ipi4: mailbox@eb370000 {
			status = "disabled";
			compatible = "xlnx,zynqmp-ipi-mailbox";
			interrupt-parent = <&imux>;
			interrupts = <0 61 4>;
			reg = <0x0 0xEB370000U 0x0 0x20>;
			xlnx,ipi-bitmask = <0x40>;
			xlnx,ipi-id = <6>;
			xlnx,ipi-buf-index = <0x6>;
			#address-cells = <2>;
			#size-cells = <2>;
			ranges;
		};

		ipi5: mailbox@eb380000 {
			status = "disabled";
			compatible = "xlnx,zynqmp-ipi-mailbox";
			interrupt-parent = <&imux>;
			interrupts = <0 62 4>;
			reg = <0x0 0xEB380000U 0x0 0x20>;
			xlnx,ipi-bitmask = <0x80>;
			xlnx,ipi-id = <7>;
			xlnx,ipi-buf-index = <0x7>;
			#address-cells = <2>;
			#size-cells = <2>;
			ranges;
		};


		ipi6: mailbox@eb3a0000 {
			status = "disabled";
			compatible = "xlnx,zynqmp-ipi-mailbox";
			interrupt-parent = <&imux>;
			interrupts = <0 63 4>;
			reg = <0x0 0xEB3a0000U 0x0 0x20>;
			xlnx,ipi-bitmask = <0x200>;
			xlnx,ipi-id = <9>;
			xlnx,ipi-buf-index = <0xffff>;
			#address-cells = <2>;
			#size-cells = <2>;
			ranges;
		};

		ipi_nobuf1: mailbox@eb3b0000 {
			status = "disabled";
			compatible = "xlnx,zynqmp-ipi-mailbox";
			interrupt-parent = <&imux>;
			interrupts = <0 64 4>;
			reg = <0x0 0xEB3B0000U 0x0 0x20>;
			xlnx,ipi-bitmask = <0x400>;
			xlnx,ipi-id = <10>;
			xlnx,ipi-buf-index = <0xffff>;
			#address-cells = <2>;
			#size-cells = <2>;
			ranges;
		};

		ipi_nobuf2: mailbox@eb3b1000 {
			status = "disabled";
			compatible = "xlnx,zynqmp-ipi-mailbox";
			interrupt-parent = <&imux>;
			interrupts = <0 65 4>;
			reg = <0x0 0xEB3B1000U 0x0 0x20>;
			xlnx,ipi-bitmask = <0x800>;
			xlnx,ipi-id = <11>;
			xlnx,ipi-buf-index = <0xffff>;
			#address-cells = <2>;
			#size-cells = <2>;
			ranges;
		};

		ipi_nobuf3: mailbox@eb3b2000 {
			status = "disabled";
			compatible = "xlnx,zynqmp-ipi-mailbox";
			interrupt-parent = <&imux>;
			interrupts = <0 66 4>;
			reg = <0x0 0xEB3B2000U 0x0 0x20>;
			xlnx,ipi-bitmask = <0x1000>;
			xlnx,ipi-id = <12>;
			xlnx,ipi-buf-index = <0xffff>;
			#address-cells = <2>;
			#size-cells = <2>;
			ranges;
		};

		ipi_nobuf4: mailbox@eb3b3000 {
			status = "disabled";
			compatible = "xlnx,zynqmp-ipi-mailbox";
			interrupt-parent = <&imux>;
			interrupts = <0 67 4>;
			reg = <0x0 0xEB3B3000U 0x0 0x20>;
			xlnx,ipi-bitmask = <0x2000>;
			xlnx,ipi-id = <13>;
			xlnx,ipi-buf-index = <0xffff>;
			#address-cells = <2>;
			#size-cells = <2>;
			ranges;
		};

		ipi_nobuf5: mailbox@eb3b4000 {
			status = "disabled";
			compatible = "xlnx,zynqmp-ipi-mailbox";
			interrupt-parent = <&imux>;
			interrupts = <0 68 4>;
			reg = <0x0 0xEB3B4000U 0x0 0x20>;
			xlnx,ipi-bitmask = <0x4000>;
			xlnx,ipi-id = <14>;
			xlnx,ipi-buf-index = <0xffff>;
			#address-cells = <2>;
			#size-cells = <2>;
			ranges;
		};

		ipi_nobuf6: mailbox@eb3b5000 {
			status = "disabled";
			compatible = "xlnx,zynqmp-ipi-mailbox";
			interrupt-parent = <&imux>;
			interrupts = <0 69 4>;
			reg = <0x0 0xEB3B5000U 0x0 0x20>;
			xlnx,ipi-bitmask = <0x8000>;
			xlnx,ipi-id = <15>;
			xlnx,ipi-buf-index = <0xffff>;
			#address-cells = <2>;
			#size-cells = <2>;
			ranges;
		};

		ipi_psm: mailbox@eb310000 {
			status = "disabled";
			compatible = "xlnx,zynqmp-ipi-mailbox";
			interrupt-parent = <&imux>;
			interrupts = <0 61 4>;
			reg = <0x0 0xEB310000U 0x0 0x20>;
			xlnx,ipi-bitmask = <0x1>;
			xlnx,ipi-id = <0>;
			xlnx,ipi-buf-index = <0x0>;
			#address-cells = <2>;
			#size-cells = <2>;
			ranges;
		};

		ipi_pmc: mailbox@eb320000 {
			status = "disabled";
			compatible = "xlnx,zynqmp-ipi-mailbox";
			interrupt-parent = <&imux>;
			interrupts = <0 59 4>;
			reg = <0x0 0xEB320000U 0x0 0x20>;
			xlnx,ipi-bitmask = <0x2>;
			xlnx,ipi-id = <1>;
			xlnx,ipi-buf-index = <0x1>;
			#address-cells = <2>;
			#size-cells = <2>;
			ranges;
		};

		ipi_pmc_nobuf: mailbox@eb390000 {
			status = "disabled";
			compatible = "xlnx,zynqmp-ipi-mailbox";
			interrupt-parent = <&imux>;
			interrupts = <0 60 4>;
			reg = <0x0 0xEB390000U 0x0 0x20>;
			xlnx,ipi-bitmask = <0x100>;
			xlnx,ipi-id = <8>;
			xlnx,ipi-buf-index = <0xffff>;
			#address-cells = <2>;
			#size-cells = <2>;
			ranges;
		};
	};
};
